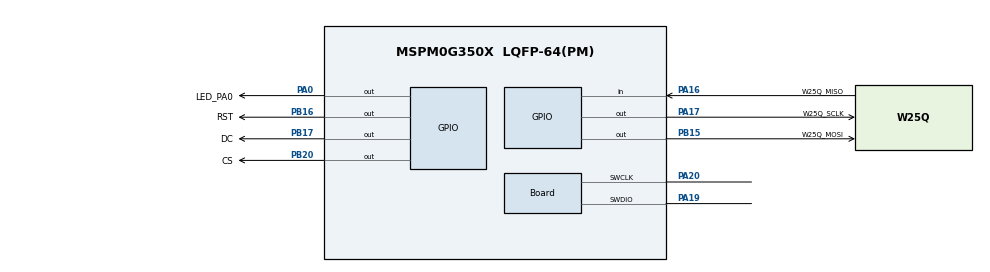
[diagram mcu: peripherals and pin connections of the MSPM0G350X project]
/**
 * @cliArgs --device "MSPM0G350X" --package "LQFP-64(PM)" --part "Default" --product "mspm0_sdk@2.00.01.00"
 * @versions {"tool":"1.20.0+3587"}
 */

/**
 * Import the modules used in this configuration.
 */
const GPIO          = scripting.addModule("/ti/driverlib/GPIO", {}, false);
const GPIO1         = GPIO.addInstance();
const GPIO2         = GPIO.addInstance();
const GPIO3         = GPIO.addInstance();
const SYSCTL        = scripting.addModule("/ti/driverlib/SYSCTL");
const SYSTICK       = scripting.addModule("/ti/driverlib/SYSTICK");
const TIMER         = scripting.addModule("/ti/driverlib/TIMER", {}, false);
const TIMER1        = TIMER.addInstance();
const ProjectConfig = scripting.addModule("/ti/project_config/ProjectConfig");

/**
 * Write custom configuration values to the imported modules.
 */
const divider9       = system.clockTree["UDIV"];
divider9.divideValue = 2;

const mux4       = system.clockTree["EXHFMUX"];
mux4.inputSelect = "EXHFMUX_XTAL";

const mux8       = system.clockTree["HSCLKMUX"];
mux8.inputSelect = "HSCLKMUX_SYSPLL2X";

const mux12       = system.clockTree["SYSPLLMUX"];
mux12.inputSelect = "zSYSPLLMUX_HFCLK";

const pinFunction4        = system.clockTree["HFXT"];
pinFunction4.enable       = true;
pinFunction4.inputFreq    = 40;
pinFunction4.HFXTStartup  = 20;
pinFunction4.HFCLKMonitor = true;

GPIO1.port                          = "PORTA";
GPIO1.$name                         = "USER_GPIO";
GPIO1.associatedPins[0].$name       = "LED_PA0";
GPIO1.associatedPins[0].pin.$assign = "PA0";

const Board                       = scripting.addModule("/ti/driverlib/Board", {}, false);
Board.peripheral.$assign          = "DEBUGSS";
Board.peripheral.swclkPin.$assign = "PA20";
Board.peripheral.swdioPin.$assign = "PA19";

GPIO2.$name                          = "PORTB";
GPIO2.associatedPins.create(4);
GPIO2.associatedPins[0].$name        = "RST";
GPIO2.associatedPins[0].initialValue = "SET";
GPIO2.associatedPins[0].pin.$assign  = "PB16";
GPIO2.associatedPins[1].$name        = "DC";
GPIO2.associatedPins[1].initialValue = "SET";
GPIO2.associatedPins[1].pin.$assign  = "PB17";
GPIO2.associatedPins[2].$name        = "CS";
GPIO2.associatedPins[2].initialValue = "SET";
GPIO2.associatedPins[2].pin.$assign  = "PB20";
GPIO2.associatedPins[3].$name        = "W25Q_MOSI";
GPIO2.associatedPins[3].pin.$assign  = "PB15";

GPIO3.$name                         = "PORTA";
GPIO3.associatedPins.create(2);
GPIO3.associatedPins[0].$name       = "W25Q_SCLK";
GPIO3.associatedPins[0].pin.$assign = "PA17";
GPIO3.associatedPins[1].$name       = "W25Q_MISO";
GPIO3.associatedPins[1].direction   = "INPUT";
GPIO3.associatedPins[1].pin.$assign = "PA16";

SYSCTL.clockTreeEn = true;

SYSTICK.periodEnable      = true;
SYSTICK.interruptEnable   = true;
SYSTICK.interruptPriority = "1";
SYSTICK.systickEnable     = true;
SYSTICK.period            = 32000;

TIMER1.timerClkPrescale   = 256;
TIMER1.timerMode          = "PERIODIC_UP";
TIMER1.timerPeriod        = "100 ms";
TIMER1.interruptPriority  = "2";
TIMER1.interrupts         = ["ZERO"];
TIMER1.$name              = "TIMER_1";
TIMER1.peripheral.$assign = "TIMA0";

ProjectConfig.deviceSpin = "MSPM0G3507";

/**
 * Pinmux solution for unlocked pins/peripherals. This ensures that minor changes to the automatic solver in a future
 * version of the tool will not impact the pinmux you originally saw.  These lines can be completely deleted in order to
 * re-solve from scratch.
 */
pinFunction4.peripheral.$suggestSolution           = "SYSCTL";
pinFunction4.peripheral.hfxInPin.$suggestSolution  = "PA5";
pinFunction4.peripheral.hfxOutPin.$suggestSolution = "PA6";
